VERSION "created by canmatrix"

NS_ :

BS_:

BU_: Tester RRLCMA RLLCMA GWM FRLCM FLLCM

BO_ 2161836032 ExtendIdTest: 8 Tester
 SG_ ExtData : 7|64@0- (1,0) [0|0] ""  RLLCMA,RRLCMA

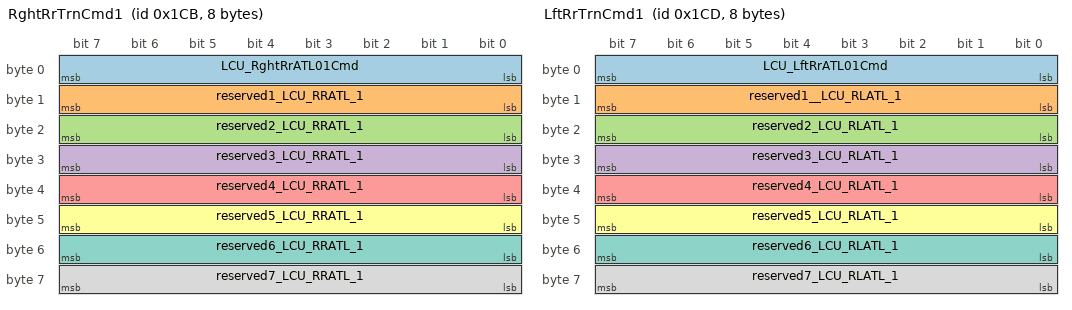
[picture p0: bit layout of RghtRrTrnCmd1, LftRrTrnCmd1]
BO_ 459 RghtRrTrnCmd1: 8 GWM
 SG_ LCU_RghtRrATL01Cmd : 7|8@0+ (1,0) [0|255] ""  RRLCMA
 SG_ reserved1_LCU_RRATL_1 : 15|8@0+ (1,0) [0|255] ""  RRLCMA
 SG_ reserved2_LCU_RRATL_1 : 23|8@0+ (1,0) [0|255] ""  RRLCMA
 SG_ reserved3_LCU_RRATL_1 : 31|8@0+ (1,0) [0|255] ""  RRLCMA
 SG_ reserved4_LCU_RRATL_1 : 39|8@0+ (1,0) [0|255] ""  RRLCMA
 SG_ reserved5_LCU_RRATL_1 : 47|8@0+ (1,0) [0|255] ""  RRLCMA
 SG_ reserved6_LCU_RRATL_1 : 55|8@0+ (1,0) [0|255] ""  RRLCMA
 SG_ reserved7_LCU_RRATL_1 : 63|8@0+ (1,0) [0|255] ""  RRLCMA

BO_ 461 LftRrTrnCmd1: 8 GWM
 SG_ LCU_LftRrATL01Cmd : 7|8@0+ (1,0) [0|255] ""  RLLCMA
 SG_ reserved1__LCU_RLATL_1 : 15|8@0+ (1,0) [0|255] ""  RLLCMA
 SG_ reserved2_LCU_RLATL_1 : 23|8@0+ (1,0) [0|255] ""  RLLCMA
 SG_ reserved3_LCU_RLATL_1 : 31|8@0+ (1,0) [0|255] ""  RLLCMA
 SG_ reserved4_LCU_RLATL_1 : 39|8@0+ (1,0) [0|255] ""  RLLCMA
 SG_ reserved5_LCU_RLATL_1 : 47|8@0+ (1,0) [0|255] ""  RLLCMA
 SG_ reserved6_LCU_RLATL_1 : 55|8@0+ (1,0) [0|255] ""  RLLCMA
 SG_ reserved7_LCU_RLATL_1 : 63|8@0+ (1,0) [0|255] ""  RLLCMA

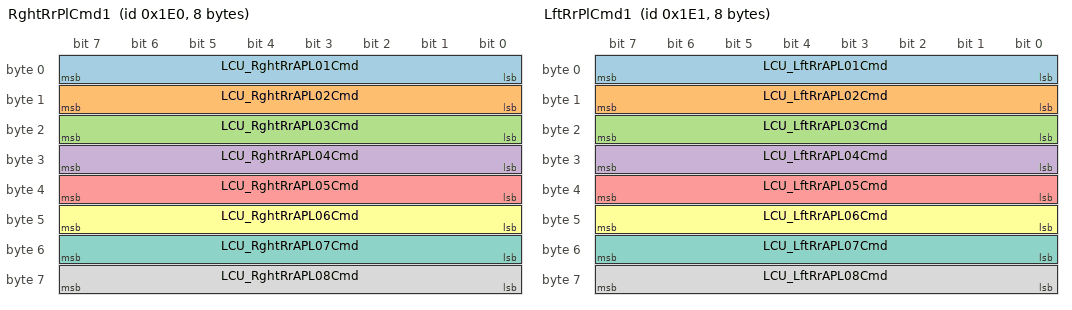
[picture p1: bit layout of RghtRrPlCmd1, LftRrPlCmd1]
BO_ 480 RghtRrPlCmd1: 8 GWM
 SG_ LCU_RghtRrAPL01Cmd : 7|8@0+ (1,0) [0|255] ""  RRLCMA
 SG_ LCU_RghtRrAPL02Cmd : 15|8@0+ (1,0) [0|255] ""  RRLCMA
 SG_ LCU_RghtRrAPL03Cmd : 23|8@0+ (1,0) [0|255] ""  RRLCMA
 SG_ LCU_RghtRrAPL04Cmd : 31|8@0+ (1,0) [0|255] ""  RRLCMA
 SG_ LCU_RghtRrAPL05Cmd : 39|8@0+ (1,0) [0|255] ""  RRLCMA
 SG_ LCU_RghtRrAPL06Cmd : 47|8@0+ (1,0) [0|255] ""  RRLCMA
 SG_ LCU_RghtRrAPL07Cmd : 55|8@0+ (1,0) [0|255] ""  RRLCMA
 SG_ LCU_RghtRrAPL08Cmd : 63|8@0+ (1,0) [0|255] ""  RRLCMA

BO_ 481 LftRrPlCmd1: 8 GWM
 SG_ LCU_LftRrAPL01Cmd : 7|8@0+ (1,0) [0|255] ""  RLLCMA
 SG_ LCU_LftRrAPL02Cmd : 15|8@0+ (1,0) [0|255] ""  RLLCMA
 SG_ LCU_LftRrAPL03Cmd : 23|8@0+ (1,0) [0|255] ""  RLLCMA
 SG_ LCU_LftRrAPL04Cmd : 31|8@0+ (1,0) [0|255] ""  RLLCMA
 SG_ LCU_LftRrAPL05Cmd : 39|8@0+ (1,0) [0|255] ""  RLLCMA
 SG_ LCU_LftRrAPL06Cmd : 47|8@0+ (1,0) [0|255] ""  RLLCMA
 SG_ LCU_LftRrAPL07Cmd : 55|8@0+ (1,0) [0|255] ""  RLLCMA
 SG_ LCU_LftRrAPL08Cmd : 63|8@0+ (1,0) [0|255] ""  RLLCMA

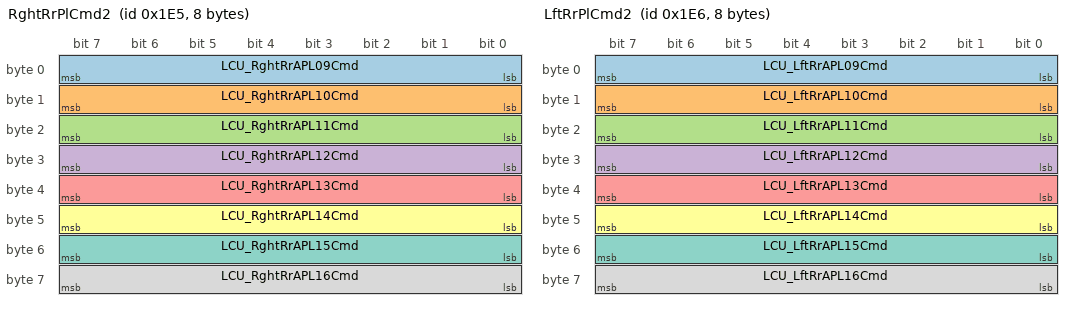
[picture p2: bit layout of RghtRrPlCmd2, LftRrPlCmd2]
BO_ 485 RghtRrPlCmd2: 8 GWM
 SG_ LCU_RghtRrAPL09Cmd : 7|8@0+ (1,0) [0|255] ""  RRLCMA
 SG_ LCU_RghtRrAPL10Cmd : 15|8@0+ (1,0) [0|255] ""  RRLCMA
 SG_ LCU_RghtRrAPL11Cmd : 23|8@0+ (1,0) [0|255] ""  RRLCMA
 SG_ LCU_RghtRrAPL12Cmd : 31|8@0+ (1,0) [0|255] ""  RRLCMA
 SG_ LCU_RghtRrAPL13Cmd : 39|8@0+ (1,0) [0|255] ""  RRLCMA
 SG_ LCU_RghtRrAPL14Cmd : 47|8@0+ (1,0) [0|255] ""  RRLCMA
 SG_ LCU_RghtRrAPL15Cmd : 55|8@0+ (1,0) [0|255] ""  RRLCMA
 SG_ LCU_RghtRrAPL16Cmd : 63|8@0+ (1,0) [0|255] ""  RRLCMA

BO_ 486 LftRrPlCmd2: 8 GWM
 SG_ LCU_LftRrAPL09Cmd : 7|8@0+ (1,0) [0|255] ""  RLLCMA
 SG_ LCU_LftRrAPL10Cmd : 15|8@0+ (1,0) [0|255] ""  RLLCMA
 SG_ LCU_LftRrAPL11Cmd : 23|8@0+ (1,0) [0|255] ""  RLLCMA
 SG_ LCU_LftRrAPL12Cmd : 31|8@0+ (1,0) [0|255] ""  RLLCMA
 SG_ LCU_LftRrAPL13Cmd : 39|8@0+ (1,0) [0|255] ""  RLLCMA
 SG_ LCU_LftRrAPL14Cmd : 47|8@0+ (1,0) [0|255] ""  RLLCMA
 SG_ LCU_LftRrAPL15Cmd : 55|8@0+ (1,0) [0|255] ""  RLLCMA
 SG_ LCU_LftRrAPL16Cmd : 63|8@0+ (1,0) [0|255] ""  RLLCMA

BO_ 489 LCU_MASTER_1: 8 GWM
 SG_ EMS_BatteryReadySt : 52|1@0+ (1,0) [0|1] "" Vector__XXX
 SG_ LCU_WelShwSts : 7|4@0+ (1,0) [0|15] ""  RRLCMA,RLLCMA,FRLCM,FLLCM
 SG_ LCU_LightShwSts : 3|4@0+ (1,0) [0|15] ""  RRLCMA,RLLCMA,FRLCM,FLLCM
 SG_ LCU_LftFrntPlSts : 15|2@0+ (1,0) [0|3] ""  RRLCMA,RLLCMA,FRLCM,FLLCM
 SG_ LCU_RghtDrlSts : 13|1@0+ (1,0) [0|1] ""  RRLCMA,RLLCMA,FRLCM,FLLCM
 SG_ LCU_LftDrlSts : 12|1@0+ (1,0) [0|1] ""  RRLCMA,RLLCMA,FRLCM,FLLCM
 SG_ LCU_RghtTrnSts : 9|1@0+ (1,0) [0|1] ""  RRLCMA,RLLCMA,FRLCM,FLLCM
 SG_ LCU_LftTrnSts : 8|1@0+ (1,0) [0|1] ""  RRLCMA,RLLCMA,FRLCM,FLLCM
 SG_ LCU_FrntFogSts : 23|1@0+ (1,0) [0|1] ""  RRLCMA,RLLCMA,FRLCM,FLLCM
 SG_ LCU_HbSts : 22|2@0+ (1,0) [0|3] ""  RRLCMA,RLLCMA,FRLCM,FLLCM
 SG_ LCU_LbSts : 20|1@0+ (1,0) [0|1] ""  RRLCMA,RLLCMA,FRLCM,FLLCM
 SG_ LCU_RghtRrPlSts : 19|1@0+ (1,0) [0|1] ""  RRLCMA,RLLCMA,FRLCM,FLLCM
 SG_ LCU_LftRrPlSts : 18|1@0+ (1,0) [0|1] ""  RRLCMA,RLLCMA,FRLCM,FLLCM
 SG_ LCU_RghtFrntPlSts : 17|2@0+ (1,0) [0|3] ""  RRLCMA,RLLCMA,FRLCM,FLLCM
 SG_ LCU_Fan2Cmd : 27|1@0+ (1,0) [0|1] ""  RRLCMA,RLLCMA,FRLCM,FLLCM
 SG_ LCU_Fan1Cmd : 26|1@0+ (1,0) [0|1] ""  RRLCMA,RLLCMA,FRLCM,FLLCM
 SG_ LCU_RrFogSts : 25|1@0+ (1,0) [0|1] ""  RRLCMA,RLLCMA,FRLCM,FLLCM
 SG_ LCU_StopSts : 24|1@0+ (1,0) [0|1] ""  RRLCMA,RLLCMA,FRLCM,FLLCM
 SG_ BCS_VehSpdVD : 37|1@0+ (1,0) [0|1] ""  RRLCMA,RLLCMA,FRLCM,FLLCM
 SG_ BCS_VehSpd : 36|13@0+ (0.05625,0) [0|8191] "km/h"  RRLCMA,RLLCMA,FRLCM,FLLCM
 SG_ EMS_EngCrankSt : 51|1@0+ (1,0) [0|1] ""  RRLCMA,RLLCMA,FRLCM,FLLCM
 SG_ EMS_EngSt : 50|1@0+ (1,0) [0|1] ""  RRLCMA,RLLCMA,FRLCM,FLLCM
 SG_ BCM_KeySt : 49|2@0+ (1,0) [0|3] ""  RRLCMA,RLLCMA,FRLCM,FLLCM

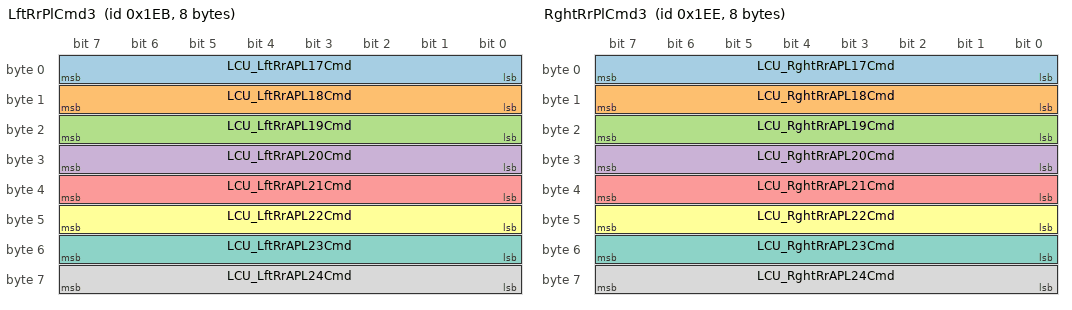
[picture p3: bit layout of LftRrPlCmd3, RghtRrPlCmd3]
BO_ 491 LftRrPlCmd3: 8 GWM
 SG_ LCU_LftRrAPL17Cmd : 7|8@0+ (1,0) [0|255] ""  RLLCMA
 SG_ LCU_LftRrAPL18Cmd : 15|8@0+ (1,0) [0|255] ""  RLLCMA
 SG_ LCU_LftRrAPL19Cmd : 23|8@0+ (1,0) [0|255] ""  RLLCMA
 SG_ LCU_LftRrAPL20Cmd : 31|8@0+ (1,0) [0|255] ""  RLLCMA
 SG_ LCU_LftRrAPL21Cmd : 39|8@0+ (1,0) [0|255] ""  RLLCMA
 SG_ LCU_LftRrAPL22Cmd : 47|8@0+ (1,0) [0|255] ""  RLLCMA
 SG_ LCU_LftRrAPL23Cmd : 55|8@0+ (1,0) [0|255] ""  RLLCMA
 SG_ LCU_LftRrAPL24Cmd : 63|8@0+ (1,0) [0|255] ""  RLLCMA

BO_ 494 RghtRrPlCmd3: 8 GWM
 SG_ LCU_RghtRrAPL17Cmd : 7|8@0+ (1,0) [0|255] ""  RRLCMA
 SG_ LCU_RghtRrAPL18Cmd : 15|8@0+ (1,0) [0|255] ""  RRLCMA
 SG_ LCU_RghtRrAPL19Cmd : 23|8@0+ (1,0) [0|255] ""  RRLCMA
 SG_ LCU_RghtRrAPL20Cmd : 31|8@0+ (1,0) [0|255] ""  RRLCMA
 SG_ LCU_RghtRrAPL21Cmd : 39|8@0+ (1,0) [0|255] ""  RRLCMA
 SG_ LCU_RghtRrAPL22Cmd : 47|8@0+ (1,0) [0|255] ""  RRLCMA
 SG_ LCU_RghtRrAPL23Cmd : 55|8@0+ (1,0) [0|255] ""  RRLCMA
 SG_ LCU_RghtRrAPL24Cmd : 63|8@0+ (1,0) [0|255] ""  RRLCMA

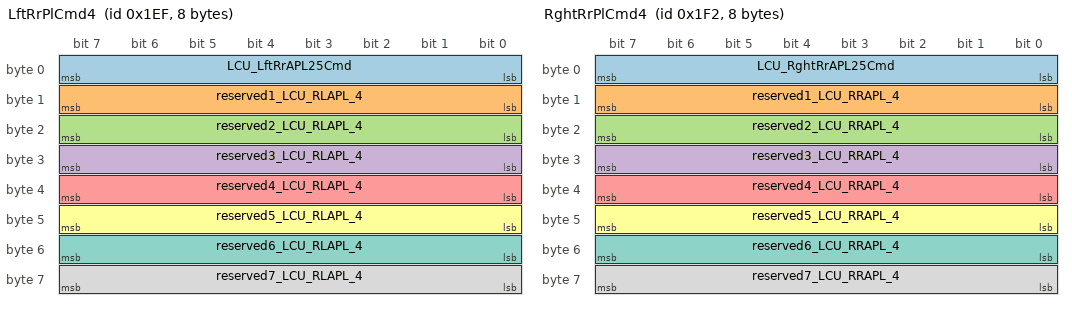
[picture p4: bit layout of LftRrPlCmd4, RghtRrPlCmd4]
BO_ 495 LftRrPlCmd4: 8 GWM
 SG_ LCU_LftRrAPL25Cmd : 7|8@0+ (1,0) [0|255] ""  RLLCMA
 SG_ reserved1_LCU_RLAPL_4 : 15|8@0+ (1,0) [0|255] ""  RLLCMA
 SG_ reserved2_LCU_RLAPL_4 : 23|8@0+ (1,0) [0|255] ""  RLLCMA
 SG_ reserved3_LCU_RLAPL_4 : 31|8@0+ (1,0) [0|255] ""  RLLCMA
 SG_ reserved4_LCU_RLAPL_4 : 39|8@0+ (1,0) [0|255] ""  RLLCMA
 SG_ reserved5_LCU_RLAPL_4 : 47|8@0+ (1,0) [0|255] ""  RLLCMA
 SG_ reserved6_LCU_RLAPL_4 : 55|8@0+ (1,0) [0|255] ""  RLLCMA
 SG_ reserved7_LCU_RLAPL_4 : 63|8@0+ (1,0) [0|255] ""  RLLCMA

BO_ 498 RghtRrPlCmd4: 8 GWM
 SG_ LCU_RghtRrAPL25Cmd : 7|8@0+ (1,0) [0|255] ""  RRLCMA
 SG_ reserved1_LCU_RRAPL_4 : 15|8@0+ (1,0) [0|255] ""  RRLCMA
 SG_ reserved2_LCU_RRAPL_4 : 23|8@0+ (1,0) [0|255] ""  RRLCMA
 SG_ reserved3_LCU_RRAPL_4 : 31|8@0+ (1,0) [0|255] ""  RRLCMA
 SG_ reserved4_LCU_RRAPL_4 : 39|8@0+ (1,0) [0|255] ""  RRLCMA
 SG_ reserved5_LCU_RRAPL_4 : 47|8@0+ (1,0) [0|255] ""  RRLCMA
 SG_ reserved6_LCU_RRAPL_4 : 55|8@0+ (1,0) [0|255] ""  RRLCMA
 SG_ reserved7_LCU_RRAPL_4 : 63|8@0+ (1,0) [0|255] ""  RRLCMA

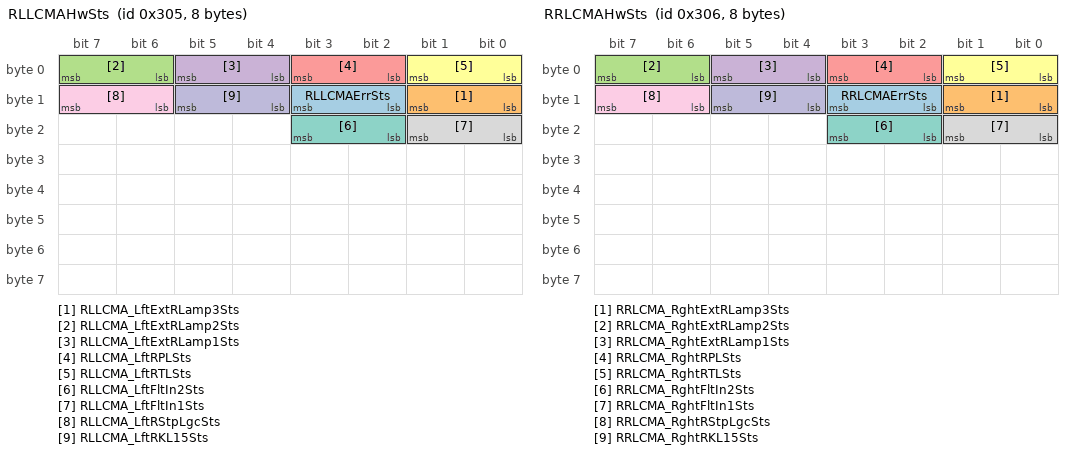
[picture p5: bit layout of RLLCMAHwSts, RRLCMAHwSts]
BO_ 773 RLLCMAHwSts: 8 RLLCMA
 SG_ RLLCMAErrSts : 11|2@0+ (1,0) [0|3] ""  GWM
 SG_ RLLCMA_LftExtRLamp3Sts : 9|2@0+ (1,0) [0|3] ""  GWM
 SG_ RLLCMA_LftExtRLamp2Sts : 7|2@0+ (1,0) [0|3] ""  GWM
 SG_ RLLCMA_LftExtRLamp1Sts : 5|2@0+ (1,0) [0|3] ""  GWM
 SG_ RLLCMA_LftRPLSts : 3|2@0+ (1,0) [0|3] ""  GWM
 SG_ RLLCMA_LftRTLSts : 1|2@0+ (1,0) [0|3] ""  GWM
 SG_ RLLCMA_LftFltIn2Sts : 19|2@0+ (1,0) [0|3] ""  GWM
 SG_ RLLCMA_LftFltIn1Sts : 17|2@0+ (1,0) [0|3] ""  GWM
 SG_ RLLCMA_LftRStpLgcSts : 15|2@0+ (1,0) [0|3] ""  GWM
 SG_ RLLCMA_LftRKL15Sts : 13|2@0+ (1,0) [0|3] ""  GWM

BO_ 774 RRLCMAHwSts: 8 RRLCMA
 SG_ RRLCMAErrSts : 11|2@0+ (1,0) [0|3] ""  GWM
 SG_ RRLCMA_RghtExtRLamp3Sts : 9|2@0+ (1,0) [0|3] ""  GWM
 SG_ RRLCMA_RghtExtRLamp2Sts : 7|2@0+ (1,0) [0|3] ""  GWM
 SG_ RRLCMA_RghtExtRLamp1Sts : 5|2@0+ (1,0) [0|3] ""  GWM
 SG_ RRLCMA_RghtRPLSts : 3|2@0+ (1,0) [0|3] ""  GWM
 SG_ RRLCMA_RghtRTLSts : 1|2@0+ (1,0) [0|3] ""  GWM
 SG_ RRLCMA_RghtFltIn2Sts : 19|2@0+ (1,0) [0|3] ""  GWM
 SG_ RRLCMA_RghtFltIn1Sts : 17|2@0+ (1,0) [0|3] ""  GWM
 SG_ RRLCMA_RghtRStpLgcSts : 15|2@0+ (1,0) [0|3] ""  GWM
 SG_ RRLCMA_RghtRKL15Sts : 13|2@0+ (1,0) [0|3] ""  GWM

BO_ 789 RLLCMALampSts: 8 RLLCMA
 SG_ RLLCMA_Bin2Err : 27|1@0+ (1,0) [0|1] "" Vector__XXX
 SG_ RLLCMA_Bin1Err : 26|1@0+ (1,0) [0|1] "" Vector__XXX
 SG_ RLLCMA_HsssErr : 7|1@0+ (1,0) [0|1] ""  GWM
 SG_ RLLCMA_Cv2Err : 6|1@0+ (1,0) [0|1] ""  GWM
 SG_ RLLCMA_Cv1Err : 5|1@0+ (1,0) [0|1] ""  GWM
 SG_ RLLCMA_LdoErr : 4|1@0+ (1,0) [0|1] ""  GWM
 SG_ RLLCMA_LostLCU : 3|1@0+ (1,0) [0|1] ""  GWM
 SG_ RLLCMA_BusOff : 2|1@0+ (1,0) [0|1] ""  GWM
 SG_ RLLCMA_Uv : 1|1@0+ (1,0) [0|1] ""  GWM
 SG_ RLLCMA_Ov : 0|1@0+ (1,0) [0|1] ""  GWM
 SG_ RLLCMA_Mtrx7Lst : 15|1@0+ (1,0) [0|1] ""  GWM
 SG_ RLLCMA_Mtrx6Lst : 14|1@0+ (1,0) [0|1] ""  GWM
 SG_ RLLCMA_Mtrx5Lst : 13|1@0+ (1,0) [0|1] ""  GWM
 SG_ RLLCMA_Mtrx4Lst : 12|1@0+ (1,0) [0|1] ""  GWM
 SG_ RLLCMA_Mtrx3Lst : 11|1@0+ (1,0) [0|1] ""  GWM
 SG_ RLLCMA_Mtrx2Lst : 10|1@0+ (1,0) [0|1] ""  GWM
 SG_ RLLCMA_Mtrx1Lst : 9|1@0+ (1,0) [0|1] ""  GWM
 SG_ RLLCMA_Mtrx0Lst : 8|1@0+ (1,0) [0|1] ""  GWM
 SG_ RLLCMA_Mtrx7LedErr : 23|1@0+ (1,0) [0|1] ""  GWM
 SG_ RLLCMA_Mtrx6LedErr : 22|1@0+ (1,0) [0|1] ""  GWM
 SG_ RLLCMA_Mtrx5LedErr : 21|1@0+ (1,0) [0|1] ""  GWM
 SG_ RLLCMA_Mtrx4LedErr : 20|1@0+ (1,0) [0|1] ""  GWM
 SG_ RLLCMA_Mtrx3LedErr : 19|1@0+ (1,0) [0|1] ""  GWM
 SG_ RLLCMA_Mtrx2LedErr : 18|1@0+ (1,0) [0|1] ""  GWM
 SG_ RLLCMA_Mtrx1LedErr : 17|1@0+ (1,0) [0|1] ""  GWM
 SG_ RLLCMA_Mtrx0LedErr : 16|1@0+ (1,0) [0|1] ""  GWM
 SG_ RLLCMA_FltIn2Warning : 25|1@0+ (1,0) [0|1] ""  GWM
 SG_ RLLCMA_FltIn1Warning : 24|1@0+ (1,0) [0|1] ""  GWM

BO_ 790 RRLCMALampSts: 8 RRLCMA
 SG_ RRLCMA_Bin2Err : 27|1@0+ (1,0) [0|1] "" Vector__XXX
 SG_ RRLCMA_Bin1Err : 26|1@0+ (1,0) [0|1] "" Vector__XXX
 SG_ RRLCMA_HsssErr : 7|1@0+ (1,0) [0|1] ""  GWM
 SG_ RRLCMA_Cv2Err : 6|1@0+ (1,0) [0|1] ""  GWM
 SG_ RRLCMA_Cv1Err : 5|1@0+ (1,0) [0|1] ""  GWM
 SG_ RRLCMA_LdoErr : 4|1@0+ (1,0) [0|1] ""  GWM
 SG_ RRLCMA_LostLCU : 3|1@0+ (1,0) [0|1] ""  GWM
 SG_ RRLCMA_BusOff : 2|1@0+ (1,0) [0|1] ""  GWM
 SG_ RRLCMA_Uv : 1|1@0+ (1,0) [0|1] ""  GWM
 SG_ RRLCMA_Ov : 0|1@0+ (1,0) [0|1] ""  GWM
 SG_ RRLCMA_Mtrx7Lst : 15|1@0+ (1,0) [0|1] ""  GWM
 SG_ RRLCMA_Mtrx6Lst : 14|1@0+ (1,0) [0|1] ""  GWM
 SG_ RRLCMA_Mtrx5Lst : 13|1@0+ (1,0) [0|1] ""  GWM
 SG_ RRLCMA_Mtrx4Lst : 12|1@0+ (1,0) [0|1] ""  GWM
 SG_ RRLCMA_Mtrx3Lst : 11|1@0+ (1,0) [0|1] ""  GWM
 SG_ RRLCMA_Mtrx2Lst : 10|1@0+ (1,0) [0|1] ""  GWM
 SG_ RRLCMA_Mtrx1Lst : 9|1@0+ (1,0) [0|1] ""  GWM
 SG_ RRLCMA_Mtrx0Lst : 8|1@0+ (1,0) [0|1] ""  GWM
 SG_ RRLCMA_Mtrx7LedErr : 23|1@0+ (1,0) [0|1] ""  GWM
 SG_ RRLCMA_Mtrx6LedErr : 22|1@0+ (1,0) [0|1] ""  GWM
 SG_ RRLCMA_Mtrx5LedErr : 21|1@0+ (1,0) [0|1] ""  GWM
 SG_ RRLCMA_Mtrx4LedErr : 20|1@0+ (1,0) [0|1] ""  GWM
 SG_ RRLCMA_Mtrx3LedErr : 19|1@0+ (1,0) [0|1] ""  GWM
 SG_ RRLCMA_Mtrx2LedErr : 18|1@0+ (1,0) [0|1] ""  GWM
 SG_ RRLCMA_Mtrx1LedErr : 17|1@0+ (1,0) [0|1] ""  GWM
 SG_ RRLCMA_Mtrx0LedErr : 16|1@0+ (1,0) [0|1] ""  GWM
 SG_ RRLCMA_FltIn2Warning : 25|1@0+ (1,0) [0|1] ""  GWM
 SG_ RRLCMA_FltIn1Warning : 24|1@0+ (1,0) [0|1] ""  GWM

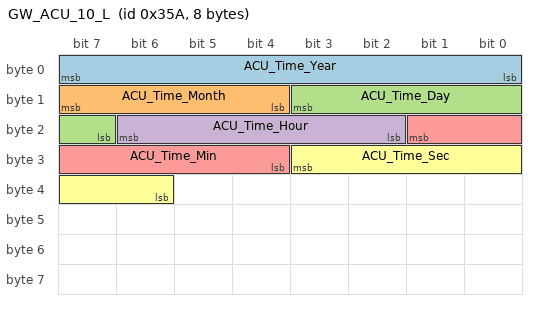
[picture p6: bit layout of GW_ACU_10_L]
BO_ 858 GW_ACU_10_L: 8 GWM
 SG_ ACU_Time_Year : 7|8@0+ (1,0) [0|255] "y"  RRLCMA,RLLCMA,FRLCM,FLLCM
 SG_ ACU_Time_Month : 15|4@0+ (1,0) [0|15] "m"  RRLCMA,RLLCMA,FRLCM,FLLCM
 SG_ ACU_Time_Day : 11|5@0+ (1,0) [0|31] "d"  RRLCMA,RLLCMA,FRLCM,FLLCM
 SG_ ACU_Time_Hour : 22|5@0+ (1,0) [0|31] "h"  RRLCMA,RLLCMA,FRLCM,FLLCM
 SG_ ACU_Time_Min : 17|6@0+ (1,0) [0|63] "min"  RRLCMA,RLLCMA,FRLCM,FLLCM
 SG_ ACU_Time_Sec : 27|6@0+ (1,0) [0|63] "s"  RRLCMA,RLLCMA,FRLCM,FLLCM

BO_ 1358 Nm_RLLCMA: 8 RLLCMA
 SG_ RLLCMA_NMNodeAddress : 7|8@0+ (1,0) [0|255] "-"  RRLCMA,GWM,FRLCM,FLLCM
 SG_ RLLCMA_NMDataField : 15|56@0+ (1,0) [0|7.20575940379279E+016] "-"  RRLCMA,GWM,FRLCM,FLLCM

BO_ 1359 Nm_LCU: 8 GWM
 SG_ GWM_NodeAddress : 7|8@0+ (1,0) [0|255] ""  RRLCMA,RLLCMA,FRLCM,FLLCM
 SG_ GWM_NMDataField : 15|56@0+ (1,0) [0|7.20575940379279E+016] ""  RRLCMA,RLLCMA,FRLCM,FLLCM

BO_ 1371 Nm_RRLCMA: 8 RRLCMA
 SG_ RRLCMA_NMNodeAddress : 7|8@0+ (1,0) [0|255] "-"  RLLCMA,GWM,FRLCM,FLLCM
 SG_ RRLCMA_NMDataField : 15|56@0+ (1,0) [0|7.20575940379279E+016] "-"  RLLCMA,GWM,FRLCM,FLLCM

BO_ 1870 PhyDiagReq_LftRrA: 8 Tester
 SG_ RLLCMA_Diag_Request : 7|64@0+ (1,0) [0|1.84467440737096E+019] ""  RLLCMA

BO_ 1883 PhyDiagReq_RghtRrA: 8 Tester
 SG_ RRLCMA_Diag_Request : 7|64@0+ (1,0) [0|1.84467440737096E+019] ""  RRLCMA

BO_ 1998 DiagResp_LftRrA: 8 RLLCMA
 SG_ RLLCMA_Diag_Response : 7|64@0+ (1,0) [0|1.84467440737096E+019] ""  Tester

BO_ 2011 DiagResp_RghtRrA: 8 RRLCMA
 SG_ RRLCMA_Diag_Response : 7|64@0+ (1,0) [0|1.84467440737096E+019] ""  Tester

BO_ 2015 FuncDiagReq: 8 Tester
 SG_ Func_Diag_Rx : 7|64@0+ (1,0) [0|1.84467440737096E+019] ""  RRLCMA,RLLCMA,FRLCM,FLLCM

CM_ BO_ 459 "LCU_RRATL_1";
CM_ SG_ 459 LCU_RghtRrATL01Cmd "Right rear A turn lamp 01 command";
CM_ BO_ 461 "LCU_RLATL_1";
CM_ SG_ 461 LCU_LftRrATL01Cmd "left rear A turn lamp 01 command";
CM_ BO_ 480 "LCU_RRAPL_1";
CM_ SG_ 480 LCU_RghtRrAPL01Cmd "Right rear A postion lamp 01 command";
CM_ SG_ 480 LCU_RghtRrAPL02Cmd "Right rear A postion lamp 02 command";
CM_ SG_ 480 LCU_RghtRrAPL03Cmd "Right rear A postion lamp 03 command";
CM_ SG_ 480 LCU_RghtRrAPL04Cmd "Right rear A postion lamp 04 command";
CM_ SG_ 480 LCU_RghtRrAPL05Cmd "Right rear A postion lamp 05 command";
CM_ SG_ 480 LCU_RghtRrAPL06Cmd "Right rear A postion lamp 06 command";
CM_ SG_ 480 LCU_RghtRrAPL07Cmd "Right rear A postion lamp 07 command";
CM_ SG_ 480 LCU_RghtRrAPL08Cmd "Right rear A postion lamp 08 command";
CM_ BO_ 481 "LCU_RLAPL_1";
CM_ SG_ 481 LCU_LftRrAPL01Cmd "Left rear A postion lamp 01 command";
CM_ SG_ 481 LCU_LftRrAPL02Cmd "Left rear A postion lamp 02 command";
CM_ SG_ 481 LCU_LftRrAPL03Cmd "Left rear A postion lamp 03 command";
CM_ SG_ 481 LCU_LftRrAPL04Cmd "Left rear A postion lamp 04 command";
CM_ SG_ 481 LCU_LftRrAPL05Cmd "Left rear A postion lamp 05 command";
CM_ SG_ 481 LCU_LftRrAPL06Cmd "Left rear A postion lamp 06 command";
CM_ SG_ 481 LCU_LftRrAPL07Cmd "Left rear A postion lamp 07 command";
CM_ SG_ 481 LCU_LftRrAPL08Cmd "Left rear A postion lamp 08 command";
CM_ BO_ 485 "LCU_RRAPL_2";
CM_ SG_ 485 LCU_RghtRrAPL09Cmd "Right rear A postion lamp 09 command";
CM_ SG_ 485 LCU_RghtRrAPL10Cmd "Right rear A postion lamp 10 command";
CM_ SG_ 485 LCU_RghtRrAPL11Cmd "Right rear A postion lamp 11 command";
CM_ SG_ 485 LCU_RghtRrAPL12Cmd "Right rear A postion lamp 12 command";
CM_ SG_ 485 LCU_RghtRrAPL13Cmd "Right rear A postion lamp 13 command";
CM_ SG_ 485 LCU_RghtRrAPL14Cmd "Right rear A postion lamp 14 command";
CM_ SG_ 485 LCU_RghtRrAPL15Cmd "Right rear A postion lamp 15 command";
CM_ SG_ 485 LCU_RghtRrAPL16Cmd "Right rear A postion lamp 16 command";
CM_ BO_ 486 "LCU_RLAPL_2";
CM_ SG_ 486 LCU_LftRrAPL09Cmd "Left rear A postion lamp 09 command";
CM_ SG_ 486 LCU_LftRrAPL10Cmd "Left rear A postion lamp 10 command";
CM_ SG_ 486 LCU_LftRrAPL11Cmd "Left rear A postion lamp 11 command";
CM_ SG_ 486 LCU_LftRrAPL12Cmd "Left rear A postion lamp 12 command";
CM_ SG_ 486 LCU_LftRrAPL13Cmd "Left rear A postion lamp 13 command";
CM_ SG_ 486 LCU_LftRrAPL14Cmd "Left rear A postion lamp 14 command";
CM_ SG_ 486 LCU_LftRrAPL15Cmd "Left rear A postion lamp 15 command";
CM_ SG_ 486 LCU_LftRrAPL16Cmd "Left rear A postion lamp 16 command";
CM_ BO_ 489 "LCU_MASTER_1";
CM_ SG_ 489 EMS_BatteryReadySt "Battery Ready status";
CM_ SG_ 489 LCU_WelShwSts "Welcome show status";
CM_ SG_ 489 LCU_LightShwSts "light show status";
CM_ SG_ 489 LCU_LftFrntPlSts "left front postion lamp status";
CM_ SG_ 489 LCU_RghtDrlSts "right day time running lamp status";
CM_ SG_ 489 LCU_LftDrlSts "left day time running lamp status";
CM_ SG_ 489 LCU_RghtTrnSts "right turn lamp status";
CM_ SG_ 489 LCU_LftTrnSts "left turn lamp status";
CM_ SG_ 489 LCU_FrntFogSts "front fog lamp status";
CM_ SG_ 489 LCU_HbSts "high beam lamp status";
CM_ SG_ 489 LCU_LbSts "low beam lamp status";
CM_ SG_ 489 LCU_RghtRrPlSts "right rear postion lamp status";
CM_ SG_ 489 LCU_LftRrPlSts "left rear postion lamp status";
CM_ SG_ 489 LCU_RghtFrntPlSts "right front postion lamp status";
CM_ SG_ 489 LCU_Fan2Cmd "cool fan2 control command";
CM_ SG_ 489 LCU_Fan1Cmd "cool fan1 control command";
CM_ SG_ 489 LCU_RrFogSts "rear fog lampstatus";
CM_ SG_ 489 LCU_StopSts "stop lamp status";
CM_ SG_ 489 BCS_VehSpdVD "Quality/fault information to vehicle speed";
CM_ SG_ 489 BCS_VehSpd "Vehicle speed";
CM_ SG_ 489 EMS_EngCrankSt "Engine crank status";
CM_ SG_ 489 EMS_EngSt "Engine running status";
CM_ SG_ 489 BCM_KeySt "Ignition key position status";
CM_ BO_ 491 "LCU_RLAPL_3";
CM_ SG_ 491 LCU_LftRrAPL17Cmd "Left rear A postion lamp 17 command";
CM_ SG_ 491 LCU_LftRrAPL18Cmd "Left rear A postion lamp 18 command";
CM_ SG_ 491 LCU_LftRrAPL19Cmd "Left rear A postion lamp 19 command";
CM_ SG_ 491 LCU_LftRrAPL20Cmd "Left rear A postion lamp 20 command";
CM_ SG_ 491 LCU_LftRrAPL21Cmd "Left rear A postion lamp 21 command";
CM_ SG_ 491 LCU_LftRrAPL22Cmd "Left rear A postion lamp 22 command";
CM_ SG_ 491 LCU_LftRrAPL23Cmd "Left rear A postion lamp 23 command";
CM_ SG_ 491 LCU_LftRrAPL24Cmd "Left rear A postion lamp 24 command";
CM_ BO_ 494 "LCU_RRAPL_3";
CM_ SG_ 494 LCU_RghtRrAPL17Cmd "Right rear A postion lamp 17 command";
CM_ SG_ 494 LCU_RghtRrAPL18Cmd "Right rear A postion lamp 18 command";
CM_ SG_ 494 LCU_RghtRrAPL19Cmd "Right rear A postion lamp 19 command";
CM_ SG_ 494 LCU_RghtRrAPL20Cmd "Right rear A postion lamp 20 command";
CM_ SG_ 494 LCU_RghtRrAPL21Cmd "Right rear A postion lamp 21 command";
CM_ SG_ 494 LCU_RghtRrAPL22Cmd "Right rear A postion lamp 22 command";
CM_ SG_ 494 LCU_RghtRrAPL23Cmd "Right rear A postion lamp 23 command";
CM_ SG_ 494 LCU_RghtRrAPL24Cmd "Right rear A postion lamp 24 command";
CM_ BO_ 495 "LCU_RLAPL_4";
CM_ SG_ 495 LCU_LftRrAPL25Cmd "Left rear A postion lamp 25 command";
CM_ BO_ 498 "LCU_RRAPL_4";
CM_ SG_ 498 LCU_RghtRrAPL25Cmd "Right rear A postion lamp 25 command";
CM_ BO_ 773 "RLLCMA_LCU_1";
CM_ SG_ 773 RLLCMAErrSts "RLLCMA module inner work status";
CM_ SG_ 773 RLLCMA_LftExtRLamp3Sts "RLLCMA left external rear lamp3 work status";
CM_ SG_ 773 RLLCMA_LftExtRLamp2Sts "RLLCMA left external rear lamp2 work status";
CM_ SG_ 773 RLLCMA_LftExtRLamp1Sts "RLLCMA left external rear lamp1 work status";
CM_ SG_ 773 RLLCMA_LftRPLSts "RLLCMA left rear position lamp work status";
CM_ SG_ 773 RLLCMA_LftRTLSts "RLLCMA left rear turn lamp work status";
CM_ SG_ 773 RLLCMA_LftFltIn2Sts "RLLCMA Left fault-in logic input2 status";
CM_ SG_ 773 RLLCMA_LftFltIn1Sts "RLLCMA Left fault-in logic input1 status";
CM_ SG_ 773 RLLCMA_LftRStpLgcSts "RLLCMA Left rear stop lamp logic input status";
CM_ SG_ 773 RLLCMA_LftRKL15Sts "RLLCMA Left rear lamp KL15 input status";
CM_ BO_ 774 "RRLCMA_LCU_1";
CM_ SG_ 774 RRLCMAErrSts "RRLCMA module inner work status";
CM_ SG_ 774 RRLCMA_RghtExtRLamp3Sts "RRLCMA Right external rear lamp3 work status";
CM_ SG_ 774 RRLCMA_RghtExtRLamp2Sts "RRLCMA Right external rear lamp2 work status";
CM_ SG_ 774 RRLCMA_RghtExtRLamp1Sts "RRLCMA Right external rear lamp1 work status";
CM_ SG_ 774 RRLCMA_RghtRPLSts "RRLCMA Right rear position lamp work status";
CM_ SG_ 774 RRLCMA_RghtRTLSts "RRLCMA Right rear turn lamp work status";
CM_ SG_ 774 RRLCMA_RghtFltIn2Sts "RRLCMA Right fault-in logic input2 status";
CM_ SG_ 774 RRLCMA_RghtFltIn1Sts "RRLCMA Right  fault-in logic input1 status";
CM_ SG_ 774 RRLCMA_RghtRStpLgcSts "RRLCMA Right rear stop lamp logic input status";
CM_ SG_ 774 RRLCMA_RghtRKL15Sts "RRLCMA Right rear lamp KL15 input status";
CM_ BO_ 789 "RLLCMA_LCU_2";
CM_ SG_ 789 RLLCMA_Bin2Err "RLLCMA power channel 2 bin fault";
CM_ SG_ 789 RLLCMA_Bin1Err "RLLCMA power channel 1 bin fault";
CM_ SG_ 789 RLLCMA_HsssErr "RLLCMA HSSS channel current out of range";
CM_ SG_ 789 RLLCMA_Cv2Err "RLLCMA constant voltage power channel2 error";
CM_ SG_ 789 RLLCMA_Cv1Err "RLLCMA constant voltage power channel1 error";
CM_ SG_ 789 RLLCMA_LdoErr "RLLCMA output 5V error";
CM_ SG_ 789 RLLCMA_LostLCU "RLLCMA module lost communication with LCU";
CM_ SG_ 789 RLLCMA_BusOff "RLLCMA module can bus off";
CM_ SG_ 789 RLLCMA_Uv "RLLCMA module power undervoltage";
CM_ SG_ 789 RLLCMA_Ov "RLLCMA module power overvoltage";
CM_ SG_ 789 RLLCMA_Mtrx7Lst "RLLCMA module lost communication with matrix chip 7#";
CM_ SG_ 789 RLLCMA_Mtrx6Lst "RLLCMA module lost communication with matrix chip 6#";
CM_ SG_ 789 RLLCMA_Mtrx5Lst "RLLCMA module lost communication with matrix chip 5#";
CM_ SG_ 789 RLLCMA_Mtrx4Lst "RLLCMA module lost communication with matrix chip 4#";
CM_ SG_ 789 RLLCMA_Mtrx3Lst "RLLCMA module lost communication with matrix chip 3#";
CM_ SG_ 789 RLLCMA_Mtrx2Lst "RLLCMA module lost communication with matrix chip 2#";
CM_ SG_ 789 RLLCMA_Mtrx1Lst "RLLCMA module lost communication with matrix chip 1#";
CM_ SG_ 789 RLLCMA_Mtrx0Lst "RLLCMA module lost communication with matrix chip 0#";
CM_ SG_ 789 RLLCMA_Mtrx7LedErr "RLLCMA Matrix chip 7# led error";
CM_ SG_ 789 RLLCMA_Mtrx6LedErr "RLLCMA Matrix chip 6# led error";
CM_ SG_ 789 RLLCMA_Mtrx5LedErr "RLLCMA Matrix chip 5# led error";
CM_ SG_ 789 RLLCMA_Mtrx4LedErr "RLLCMA Matrix chip 4# led error";
CM_ SG_ 789 RLLCMA_Mtrx3LedErr "RLLCMA Matrix chip 3# led error";
CM_ SG_ 789 RLLCMA_Mtrx2LedErr "RLLCMA Matrix chip 2# led error";
CM_ SG_ 789 RLLCMA_Mtrx1LedErr "RLLCMA Matrix chip 1# led error";
CM_ SG_ 789 RLLCMA_Mtrx0LedErr "RLLCMA Matrix chip 0# led error";
CM_ SG_ 789 RLLCMA_FltIn2Warning "RLLCMA fault input2 warning";
CM_ SG_ 789 RLLCMA_FltIn1Warning "RLLCMA fault input1 warning";
CM_ BO_ 790 "RRLCMA_LCU_2";
CM_ SG_ 790 RRLCMA_Bin2Err "RRLCMA power channel 2 bin fault";
CM_ SG_ 790 RRLCMA_Bin1Err "RRLCMA power channel 1 bin fault";
CM_ SG_ 790 RRLCMA_HsssErr "RRLCMA HSSS channel current out of range";
CM_ SG_ 790 RRLCMA_Cv2Err "RRLCMA constant voltage power channel2 error";
CM_ SG_ 790 RRLCMA_Cv1Err "RRLCMA constant voltage power channel1 error";
CM_ SG_ 790 RRLCMA_LdoErr "RRLCMA output 5V error";
CM_ SG_ 790 RRLCMA_LostLCU "RRLCMA module lost communication with LCU";
CM_ SG_ 790 RRLCMA_BusOff "RRLCMA module can bus off";
CM_ SG_ 790 RRLCMA_Uv "RRLCMA module power undervoltage";
CM_ SG_ 790 RRLCMA_Ov "RRLCMA module power overvoltage";
CM_ SG_ 790 RRLCMA_Mtrx7Lst "RRLCMA module lost communication with matrix chip 7#";
CM_ SG_ 790 RRLCMA_Mtrx6Lst "RRLCMA module lost communication with matrix chip 6#";
CM_ SG_ 790 RRLCMA_Mtrx5Lst "RRLCMA module lost communication with matrix chip 5#";
CM_ SG_ 790 RRLCMA_Mtrx4Lst "RRLCMA module lost communication with matrix chip 4#";
CM_ SG_ 790 RRLCMA_Mtrx3Lst "RRLCMA module lost communication with matrix chip 3#";
CM_ SG_ 790 RRLCMA_Mtrx2Lst "RRLCMA module lost communication with matrix chip 2#";
CM_ SG_ 790 RRLCMA_Mtrx1Lst "RRLCMA module lost communication with matrix chip 1#";
CM_ SG_ 790 RRLCMA_Mtrx0Lst "RRLCMA module lost communication with matrix chip 0#";
CM_ SG_ 790 RRLCMA_Mtrx7LedErr "RRLCMA Matrix chip 7# led error";
CM_ SG_ 790 RRLCMA_Mtrx6LedErr "RRLCMA Matrix chip 6# led error";
CM_ SG_ 790 RRLCMA_Mtrx5LedErr "RRLCMA Matrix chip 5# led error";
CM_ SG_ 790 RRLCMA_Mtrx4LedErr "RRLCMA Matrix chip 4# led error";
CM_ SG_ 790 RRLCMA_Mtrx3LedErr "RRLCMA Matrix chip 3# led error";
CM_ SG_ 790 RRLCMA_Mtrx2LedErr "RRLCMA Matrix chip 2# led error";
CM_ SG_ 790 RRLCMA_Mtrx1LedErr "RRLCMA Matrix chip 1# led error";
CM_ SG_ 790 RRLCMA_Mtrx0LedErr "RRLCMA Matrix chip 0# led error";
CM_ SG_ 790 RRLCMA_FltIn2Warning "RRLCMA fault input2 warning";
CM_ SG_ 790 RRLCMA_FltIn1Warning "RRLCMA fault input1 warning";
CM_ BO_ 858 "GW_ACU_10_L";
CM_ SG_ 858 ACU_Time_Year "Year number";
CM_ SG_ 858 ACU_Time_Month "Month number";
CM_ SG_ 858 ACU_Time_Day "Day number";
CM_ SG_ 858 ACU_Time_Hour "Hour number";
CM_ SG_ 858 ACU_Time_Min "Minute number";
CM_ SG_ 858 ACU_Time_Sec "Second number";
CM_ BO_ 1358 "RLLCMA_NM_LCAN";
CM_ SG_ 1358 RLLCMA_NMNodeAddress "RLLCMA  node address";
CM_ SG_ 1358 RLLCMA_NMDataField "RLLCMA Network management data";
CM_ BO_ 1359 "GWM_LCAN_NM";
CM_ SG_ 1359 GWM_NodeAddress "GWM node adress";
CM_ SG_ 1359 GWM_NMDataField "GWM Network management data";
CM_ BO_ 1371 "RRLCMA_NM_LCAN";
CM_ SG_ 1371 RRLCMA_NMNodeAddress "RRLCMA  node address";
CM_ SG_ 1371 RRLCMA_NMDataField "RRLCMA Network management data";
CM_ BO_ 1870 "RLLCMA_Diag_Rx";
CM_ SG_ 1870 RLLCMA_Diag_Request "Diagnostic physical request";
CM_ BO_ 1883 "RRLCMA_Diag_Rx";
CM_ SG_ 1883 RRLCMA_Diag_Request "Diagnostic physical request";
CM_ BO_ 1998 "RLLCMA_Diag_Tx";
CM_ SG_ 1998 RLLCMA_Diag_Response "Diagnostic  response";
CM_ BO_ 2011 "RRLCMA_Diag_Tx";
CM_ SG_ 2011 RRLCMA_Diag_Response "Diagnostic  response";
BA_DEF_ BO_  "GenMsgSendType" ENUM  "Cyclic","NotUsed","NotUsed","NotUsed","NotUsed","NotUsed","NotUsed","NotUsed","NoMsgSendType";
BA_DEF_ SG_  "GenSigSendOnInit" ENUM  "Not Initialized","Application","Handler";
BA_DEF_ SG_  "GenSigSendType" ENUM  "NotUsed","OnWrite","OnWriteWithRepetition","OnChange","OnChangeWithRepetition","IfActive","IfActiveWithRepeition","NoSigSendType";
BA_DEF_ BO_  "GenMsgILSupport" ENUM  "No","Yes";
BA_DEF_ BO_  "DiagRequest" ENUM  "No","Yes";
BA_DEF_ BO_  "DiagResponse" ENUM  "No","Yes";
BA_DEF_ BO_  "DiagState" ENUM  "No","Yes";
BA_DEF_ BO_  "MessageSubnet" ENUM  "BB","PB","CB","Body","HS","Powertrain","Chassis","Spare","PE","CC";
BA_DEF_ BU_  "ECU_Id" HEX 0 255;
BA_DEF_ BU_  "ILUsed" ENUM  "No","Yes";
BA_DEF_ BU_  "SourceId" HEX 0 255;
BA_DEF_ BU_  "NmAsrNode" ENUM  "No","Yes";
BA_DEF_ BU_  "NmAsrNodeIdentifier" HEX 0 159;
BA_DEF_ BU_  "NmAsrCanMsgReducedTime" INT 0 65535;
BA_DEF_  "DBName" STRING ;
BA_DEF_  "NmType" STRING ;
BA_DEF_  "Baudrate" INT 0 1000000;
BA_DEF_  "BusOffRecoveryTime" INT 0 65535;
BA_DEF_  "Manufacturer" STRING ;
BA_DEF_  "SamplePointMin" FLOAT 0 100;
BA_DEF_  "SamplePointMax" FLOAT 0 100;
BA_DEF_  "SyncJumpWidthMin" INT 0 255;
BA_DEF_  "SyncJumpWidthMax" INT 0 255;
BA_DEF_  "BusType" STRING ;
BA_DEF_  "NmAsrMessageCount" INT 0 256;
BA_DEF_  "NmAsrBaseAddress" HEX 0 2032;
BA_DEF_  "NmAsrTimeoutTime" INT 0 65535;
BA_DEF_  "NmAsrWaitBusSleepTime" INT 0 65535;
BA_DEF_  "NmAsrRepeatMessageTime" INT 0 65525;
BA_DEF_  "NmAsrCanMsgCycleTime" INT 0 65535;
BA_DEF_ BO_  "GenMsgCycleTime" INT 0 65535;
BA_DEF_ BU_ "NodeLayerModules" STRING ;
BA_DEF_REL_ BU_SG_REL_  "GenSigTimeoutMsg" HEX 0 65535;
BA_DEF_REL_ BU_SG_REL_  "GenSigTimeoutTime" INT 0 15000;
BA_DEF_DEF_  "GenMsgSendType" "NoMsgSendType";
BA_DEF_DEF_  "GenSigSendOnInit" "Not Initialized";
BA_DEF_DEF_  "GenSigSendType" "NoSigSendType";
BA_DEF_DEF_  "GenMsgILSupport" "Yes";
BA_DEF_DEF_  "DiagRequest" "No";
BA_DEF_DEF_  "DiagResponse" "No";
BA_DEF_DEF_  "DiagState" "No";
BA_DEF_DEF_  "MessageSubnet" "Body";
BA_DEF_DEF_  "ECU_Id" 0;
BA_DEF_DEF_  "ILUsed" "Yes";
BA_DEF_DEF_  "SourceId" 0;
BA_DEF_DEF_  "NmAsrNode" "Yes";
BA_DEF_DEF_  "NmAsrNodeIdentifier" 0;
BA_DEF_DEF_  "NmAsrCanMsgReducedTime" 0;
BA_DEF_DEF_  "DBName" "SubCAN";
BA_DEF_DEF_  "NmType" "NmAsr";
BA_DEF_DEF_  "Baudrate" 500000;
BA_DEF_DEF_  "BusOffRecoveryTime" 160;
BA_DEF_DEF_  "Manufacturer" "GM";
BA_DEF_DEF_  "SamplePointMin" 81.25;
BA_DEF_DEF_  "SamplePointMax" 80;
BA_DEF_DEF_  "SyncJumpWidthMin" 4;
BA_DEF_DEF_  "SyncJumpWidthMax" 3;
BA_DEF_DEF_  "BusType" "CAN";
BA_DEF_DEF_  "NmAsrMessageCount" 16;
BA_DEF_DEF_  "NmAsrBaseAddress" 0;
BA_DEF_DEF_  "NmAsrTimeoutTime" 1500;
BA_DEF_DEF_  "NmAsrWaitBusSleepTime" 750;
BA_DEF_DEF_  "NmAsrRepeatMessageTime" 400;
BA_DEF_DEF_  "NmAsrCanMsgCycleTime" 1000;
BA_DEF_DEF_  "GenMsgCycleTime" 0;
BA_DEF_DEF_REL_ "GenSigTimeoutMsg" 0;
BA_DEF_DEF_REL_ "GenSigTimeoutTime" 0;
BA_DEF_DEF_ "NodeLayerModules" "";
BA_ "BusOffRecoveryTime" 200;
BA_ "NmAsrBaseAddress" 1312;
BA_ "NmAsrTimeoutTime" 1000;
BA_ "NmAsrWaitBusSleepTime" 5000;
BA_ "NmAsrCanMsgCycleTime" 200;
BA_ "DBName" "PB";
BA_ "SourceId" BU_ RRLCMA 1;
BA_ "ECU_Id" BU_ RRLCMA 1;
BA_ "NmAsrCanMsgReducedTime" BU_ RLLCMA 500;
BA_ "NmAsrNodeIdentifier" BU_ RLLCMA 1;
BA_ "MessageSubnet" BO_ 2161836032 1;
BA_ "GenMsgSendType" BO_ 459 0;
BA_ "GenMsgCycleTime" BO_ 459 20;
BA_ "MessageSubnet" BO_ 459 1;
BA_ "GenMsgSendType" BO_ 461 0;
BA_ "GenMsgCycleTime" BO_ 461 20;
BA_ "MessageSubnet" BO_ 461 1;
BA_ "GenMsgSendType" BO_ 480 0;
BA_ "GenMsgCycleTime" BO_ 480 20;
BA_ "MessageSubnet" BO_ 480 1;
BA_ "GenMsgSendType" BO_ 481 0;
BA_ "GenMsgCycleTime" BO_ 481 20;
BA_ "MessageSubnet" BO_ 481 1;
BA_ "GenMsgSendType" BO_ 485 0;
BA_ "GenMsgCycleTime" BO_ 485 20;
BA_ "MessageSubnet" BO_ 485 1;
BA_ "GenMsgSendType" BO_ 486 0;
BA_ "GenMsgCycleTime" BO_ 486 20;
BA_ "MessageSubnet" BO_ 486 1;
BA_ "GenMsgSendType" BO_ 489 0;
BA_ "GenMsgCycleTime" BO_ 489 20;
BA_ "MessageSubnet" BO_ 489 1;
BA_ "GenMsgSendType" BO_ 491 0;
BA_ "GenMsgCycleTime" BO_ 491 20;
BA_ "MessageSubnet" BO_ 491 1;
BA_ "GenMsgSendType" BO_ 494 0;
BA_ "GenMsgCycleTime" BO_ 494 20;
BA_ "MessageSubnet" BO_ 494 1;
BA_ "GenMsgSendType" BO_ 495 0;
BA_ "GenMsgCycleTime" BO_ 495 20;
BA_ "MessageSubnet" BO_ 495 1;
BA_ "GenMsgSendType" BO_ 498 0;
BA_ "GenMsgCycleTime" BO_ 498 20;
BA_ "MessageSubnet" BO_ 498 1;
BA_ "GenMsgSendType" BO_ 773 0;
BA_ "GenMsgCycleTime" BO_ 773 100;
BA_ "MessageSubnet" BO_ 773 1;
BA_ "GenMsgSendType" BO_ 774 0;
BA_ "GenMsgCycleTime" BO_ 774 100;
BA_ "MessageSubnet" BO_ 774 1;
BA_ "GenMsgSendType" BO_ 789 0;
BA_ "GenMsgCycleTime" BO_ 789 100;
BA_ "MessageSubnet" BO_ 789 1;
BA_ "GenMsgSendType" BO_ 790 0;
BA_ "GenMsgCycleTime" BO_ 790 100;
BA_ "MessageSubnet" BO_ 790 1;
BA_ "GenMsgSendType" BO_ 858 0;
BA_ "GenMsgCycleTime" BO_ 858 500;
BA_ "MessageSubnet" BO_ 858 1;
BA_ "GenMsgSendType" BO_ 1358 0;
BA_ "GenMsgCycleTime" BO_ 1358 200;
BA_ "MessageSubnet" BO_ 1358 1;
BA_ "GenMsgSendType" BO_ 1359 0;
BA_ "GenMsgCycleTime" BO_ 1359 200;
BA_ "MessageSubnet" BO_ 1359 1;
BA_ "GenMsgSendType" BO_ 1371 0;
BA_ "GenMsgCycleTime" BO_ 1371 200;
BA_ "MessageSubnet" BO_ 1371 1;
BA_ "GenMsgILSupport" BO_ 1870 0;
BA_ "DiagRequest" BO_ 1870 1;
BA_ "MessageSubnet" BO_ 1870 1;
BA_ "GenMsgILSupport" BO_ 1883 0;
BA_ "DiagRequest" BO_ 1883 1;
BA_ "MessageSubnet" BO_ 1883 1;
BA_ "GenMsgILSupport" BO_ 1998 0;
BA_ "DiagResponse" BO_ 1998 1;
BA_ "MessageSubnet" BO_ 1998 1;
BA_ "GenMsgILSupport" BO_ 2011 0;
BA_ "DiagResponse" BO_ 2011 1;
BA_ "MessageSubnet" BO_ 2011 1;
BA_ "DiagState" BO_ 2015 1;
BA_ "MessageSubnet" BO_ 2015 1;
BA_ "NodeLayerModules" BU_ GWM "CANoeILNLVector.dll,AsrNM33.dll";
BA_ "NodeLayerModules" BU_ RLLCMA "CANoeILNLVector.dll,AsrNM33.dll";
BA_ "NodeLayerModules" BU_ RRLCMA "CANoeILNLVector.dll,AsrNM33.dll";
BA_ "NodeLayerModules" BU_ Tester "CANoeILNLVector.dll,AsrNM33.dll";
BA_REL_ "GenSigTimeoutMsg" BU_SG_REL_ RRLCMA SG_ 459 LCU_RghtRrATL01Cmd 459;
BA_REL_ "GenSigTimeoutTime" BU_SG_REL_ RRLCMA SG_ 459 LCU_RghtRrATL01Cmd 500;
BA_REL_ "GenSigTimeoutMsg" BU_SG_REL_ RLLCMA SG_ 461 LCU_LftRrATL01Cmd 461;
BA_REL_ "GenSigTimeoutTime" BU_SG_REL_ RLLCMA SG_ 461 LCU_LftRrATL01Cmd 500;
BA_REL_ "GenSigTimeoutMsg" BU_SG_REL_ RRLCMA SG_ 480 LCU_RghtRrAPL01Cmd 480;
BA_REL_ "GenSigTimeoutTime" BU_SG_REL_ RRLCMA SG_ 480 LCU_RghtRrAPL01Cmd 500;
BA_REL_ "GenSigTimeoutMsg" BU_SG_REL_ RLLCMA SG_ 481 LCU_LftRrAPL01Cmd 481;
BA_REL_ "GenSigTimeoutTime" BU_SG_REL_ RLLCMA SG_ 481 LCU_LftRrAPL01Cmd 500;
BA_REL_ "GenSigTimeoutMsg" BU_SG_REL_ RRLCMA SG_ 485 LCU_RghtRrAPL09Cmd 485;
BA_REL_ "GenSigTimeoutTime" BU_SG_REL_ RRLCMA SG_ 485 LCU_RghtRrAPL09Cmd 500;
BA_REL_ "GenSigTimeoutMsg" BU_SG_REL_ RLLCMA SG_ 486 LCU_LftRrAPL09Cmd 486;
BA_REL_ "GenSigTimeoutTime" BU_SG_REL_ RLLCMA SG_ 486 LCU_LftRrAPL09Cmd 500;
BA_REL_ "GenSigTimeoutMsg" BU_SG_REL_ RRLCMA SG_ 489 LCU_LightShwSts 489;
BA_REL_ "GenSigTimeoutTime" BU_SG_REL_ RRLCMA SG_ 489 LCU_LightShwSts 500;
BA_REL_ "GenSigTimeoutMsg" BU_SG_REL_ RLLCMA SG_ 489 LCU_LightShwSts 489;
BA_REL_ "GenSigTimeoutTime" BU_SG_REL_ RLLCMA SG_ 489 LCU_LightShwSts 500;
BA_REL_ "GenSigTimeoutMsg" BU_SG_REL_ RLLCMA SG_ 491 LCU_LftRrAPL17Cmd 491;
BA_REL_ "GenSigTimeoutTime" BU_SG_REL_ RLLCMA SG_ 491 LCU_LftRrAPL17Cmd 500;
BA_REL_ "GenSigTimeoutMsg" BU_SG_REL_ RRLCMA SG_ 494 LCU_RghtRrAPL17Cmd 494;
BA_REL_ "GenSigTimeoutTime" BU_SG_REL_ RRLCMA SG_ 494 LCU_RghtRrAPL17Cmd 500;
BA_REL_ "GenSigTimeoutMsg" BU_SG_REL_ RLLCMA SG_ 495 LCU_LftRrAPL25Cmd 495;
BA_REL_ "GenSigTimeoutTime" BU_SG_REL_ RLLCMA SG_ 495 LCU_LftRrAPL25Cmd 500;
BA_REL_ "GenSigTimeoutMsg" BU_SG_REL_ RRLCMA SG_ 498 LCU_RghtRrAPL25Cmd 498;
BA_REL_ "GenSigTimeoutTime" BU_SG_REL_ RRLCMA SG_ 498 LCU_RghtRrAPL25Cmd 500;
BA_REL_ "GenSigTimeoutMsg" BU_SG_REL_ RRLCMA SG_ 858 ACU_Time_Year 858;
BA_REL_ "GenSigTimeoutTime" BU_SG_REL_ RRLCMA SG_ 858 ACU_Time_Year 3000;
BA_REL_ "GenSigTimeoutMsg" BU_SG_REL_ RLLCMA SG_ 858 ACU_Time_Year 858;
BA_REL_ "GenSigTimeoutTime" BU_SG_REL_ RLLCMA SG_ 858 ACU_Time_Year 3000;
BA_REL_ "GenSigTimeoutMsg" BU_SG_REL_ RRLCMA SG_ 1359 GWM_NodeAddress 1359;
BA_REL_ "GenSigTimeoutTime" BU_SG_REL_ RRLCMA SG_ 1359 GWM_NodeAddress 1000;
BA_REL_ "GenSigTimeoutMsg" BU_SG_REL_ RLLCMA SG_ 1359 GWM_NodeAddress 1359;
BA_REL_ "GenSigTimeoutTime" BU_SG_REL_ RLLCMA SG_ 1359 GWM_NodeAddress 1000;
VAL_ 489 EMS_BatteryReadySt 0 "Not on crank" 1 "On crank" ;
VAL_ 489 LCU_WelShwSts 0 "no show" 1 "welcome mode 1" 2 "welcome mode 2" 3 "welcome mode 3" 4 "welcome mode 4" 5 "welcome mode 5" 6 "welcome mode 6" 7 "reserved" 8 "reserved" 9 "reserved" 10 "reserved" 11 "reserved" 12 "reserved" 13 "reserved" 14 "reserved" 15 "reserved" ;
VAL_ 489 LCU_LightShwSts 0 "no show" 1 "light show mode 1" 2 "light show mode 2" 3 "light show mode 3" 4 "light show mode 4" 5 "light show mode 5" 6 "light show mode 6" 7 "reserved" 8 "reserved" 9 "reserved" 10 "reserved" 11 "reserved" 12 "reserved" 13 "reserved" 14 "reserved" 15 "reserved" ;
VAL_ 489 LCU_LftFrntPlSts 0 "off" 1 "PL mode on" 2 "special mode on" ;
VAL_ 489 LCU_RghtDrlSts 0 "off" 1 "on" ;
VAL_ 489 LCU_LftDrlSts 0 "off" 1 "on" ;
VAL_ 489 LCU_RghtTrnSts 0 "off" 1 "on" ;
VAL_ 489 LCU_LftTrnSts 0 "off" 1 "on" ;
VAL_ 489 LCU_FrntFogSts 0 "off" 1 "on" ;
VAL_ 489 LCU_HbSts 0 "off" 1 "normal on" 2 "ADB mode" ;
VAL_ 489 LCU_LbSts 0 "off" 1 "on" ;
VAL_ 489 LCU_RghtRrPlSts 0 "off" 1 "on" ;
VAL_ 489 LCU_LftRrPlSts 0 "off" 1 "on" ;
VAL_ 489 LCU_RghtFrntPlSts 0 "off" 1 "PL mode on" 2 "special mode on" ;
VAL_ 489 LCU_Fan2Cmd 0 "off" 1 "on" ;
VAL_ 489 LCU_Fan1Cmd 0 "off" 1 "on" ;
VAL_ 489 LCU_RrFogSts 0 "off" 1 "on" ;
VAL_ 489 LCU_StopSts 0 "off" 1 "on" ;
VAL_ 489 BCS_VehSpdVD 0 "Not Valid" 1 "Valid" ;
VAL_ 489 EMS_EngCrankSt 0 "Not on crank" 1 "On crank" ;
VAL_ 489 EMS_EngSt 0 "Not run" 1 "Run" ;
VAL_ 773 RLLCMAErrSts 0 "normal" 1 "fail" ;
VAL_ 773 RLLCMA_LftExtRLamp3Sts 0 "off" 1 "on" 2 "fail" ;
VAL_ 773 RLLCMA_LftExtRLamp2Sts 0 "off" 1 "on" 2 "fail" ;
VAL_ 773 RLLCMA_LftExtRLamp1Sts 0 "off" 1 "on" 2 "fail" ;
VAL_ 773 RLLCMA_LftRPLSts 0 "off" 1 "on" 2 "fail" ;
VAL_ 773 RLLCMA_LftRTLSts 0 "off" 1 "on" 2 "fail" ;
VAL_ 773 RLLCMA_LftFltIn2Sts 0 "low level" 1 "high level" ;
VAL_ 773 RLLCMA_LftFltIn1Sts 0 "low level" 1 "high level" ;
VAL_ 773 RLLCMA_LftRStpLgcSts 0 "low level" 1 "high level" ;
VAL_ 773 RLLCMA_LftRKL15Sts 0 "low level" 1 "high level" ;
VAL_ 774 RRLCMAErrSts 0 "normal" 1 "fail" ;
VAL_ 774 RRLCMA_RghtExtRLamp3Sts 0 "off" 1 "on" 2 "fail" ;
VAL_ 774 RRLCMA_RghtExtRLamp2Sts 0 "off" 1 "on" 2 "fail" ;
VAL_ 774 RRLCMA_RghtExtRLamp1Sts 0 "off" 1 "on" 2 "fail" ;
VAL_ 774 RRLCMA_RghtRPLSts 0 "off" 1 "on" 2 "fail" ;
VAL_ 774 RRLCMA_RghtRTLSts 0 "off" 1 "on" 2 "fail" ;
VAL_ 774 RRLCMA_RghtFltIn2Sts 0 "low level" 1 "high level" ;
VAL_ 774 RRLCMA_RghtFltIn1Sts 0 "low level" 1 "high level" ;
VAL_ 774 RRLCMA_RghtRStpLgcSts 0 "low level" 1 "high level" ;
VAL_ 774 RRLCMA_RghtRKL15Sts 0 "low level" 1 "high level" ;
VAL_ 789 RLLCMA_Bin2Err 0 "normal" 1 "fail" ;
VAL_ 789 RLLCMA_Bin1Err 0 "normal" 1 "fail" ;
VAL_ 789 RLLCMA_HsssErr 0 "normal" 1 "fail" ;
VAL_ 789 RLLCMA_Cv2Err 0 "normal" 1 "fail" ;
VAL_ 789 RLLCMA_Cv1Err 0 "normal" 1 "fail" ;
VAL_ 789 RLLCMA_LdoErr 0 "normal" 1 "fail" ;
VAL_ 789 RLLCMA_LostLCU 0 "normal" 1 "fail" ;
VAL_ 789 RLLCMA_BusOff 0 "normal" 1 "fail" ;
VAL_ 789 RLLCMA_Uv 0 "normal" 1 "fail" ;
VAL_ 789 RLLCMA_Ov 0 "normal" 1 "fail" ;
VAL_ 789 RLLCMA_Mtrx7Lst 0 "normal" 1 "fail" ;
VAL_ 789 RLLCMA_Mtrx6Lst 0 "normal" 1 "fail" ;
VAL_ 789 RLLCMA_Mtrx5Lst 0 "normal" 1 "fail" ;
VAL_ 789 RLLCMA_Mtrx4Lst 0 "normal" 1 "fail" ;
VAL_ 789 RLLCMA_Mtrx3Lst 0 "normal" 1 "fail" ;
VAL_ 789 RLLCMA_Mtrx2Lst 0 "normal" 1 "fail" ;
VAL_ 789 RLLCMA_Mtrx1Lst 0 "normal" 1 "fail" ;
VAL_ 789 RLLCMA_Mtrx0Lst 0 "normal" 1 "fail" ;
VAL_ 789 RLLCMA_Mtrx7LedErr 0 "normal" 1 "fail" ;
VAL_ 789 RLLCMA_Mtrx6LedErr 0 "normal" 1 "fail" ;
VAL_ 789 RLLCMA_Mtrx5LedErr 0 "normal" 1 "fail" ;
VAL_ 789 RLLCMA_Mtrx4LedErr 0 "normal" 1 "fail" ;
VAL_ 789 RLLCMA_Mtrx3LedErr 0 "normal" 1 "fail" ;
VAL_ 789 RLLCMA_Mtrx2LedErr 0 "normal" 1 "fail" ;
VAL_ 789 RLLCMA_Mtrx1LedErr 0 "normal" 1 "fail" ;
VAL_ 789 RLLCMA_Mtrx0LedErr 0 "normal" 1 "fail" ;
VAL_ 789 RLLCMA_FltIn2Warning 0 "normal" 1 "fail" ;
VAL_ 789 RLLCMA_FltIn1Warning 0 "normal" 1 "fail" ;
VAL_ 790 RRLCMA_Bin2Err 0 "normal" 1 "fail" ;
VAL_ 790 RRLCMA_Bin1Err 0 "normal" 1 "fail" ;
VAL_ 790 RRLCMA_HsssErr 0 "normal" 1 "fail" ;
VAL_ 790 RRLCMA_Cv2Err 0 "normal" 1 "fail" ;
VAL_ 790 RRLCMA_Cv1Err 0 "normal" 1 "fail" ;
VAL_ 790 RRLCMA_LdoErr 0 "normal" 1 "fail" ;
VAL_ 790 RRLCMA_LostLCU 0 "normal" 1 "fail" ;
VAL_ 790 RRLCMA_BusOff 0 "normal" 1 "fail" ;
VAL_ 790 RRLCMA_Uv 0 "normal" 1 "fail" ;
VAL_ 790 RRLCMA_Ov 0 "normal" 1 "fail" ;
VAL_ 790 RRLCMA_Mtrx7Lst 0 "normal" 1 "fail" ;
VAL_ 790 RRLCMA_Mtrx6Lst 0 "normal" 1 "fail" ;
VAL_ 790 RRLCMA_Mtrx5Lst 0 "normal" 1 "fail" ;
VAL_ 790 RRLCMA_Mtrx4Lst 0 "normal" 1 "fail" ;
VAL_ 790 RRLCMA_Mtrx3Lst 0 "normal" 1 "fail" ;
VAL_ 790 RRLCMA_Mtrx2Lst 0 "normal" 1 "fail" ;
VAL_ 790 RRLCMA_Mtrx1Lst 0 "normal" 1 "fail" ;
VAL_ 790 RRLCMA_Mtrx0Lst 0 "normal" 1 "fail" ;
VAL_ 790 RRLCMA_Mtrx7LedErr 0 "normal" 1 "fail" ;
VAL_ 790 RRLCMA_Mtrx6LedErr 0 "normal" 1 "fail" ;
VAL_ 790 RRLCMA_Mtrx5LedErr 0 "normal" 1 "fail" ;
VAL_ 790 RRLCMA_Mtrx4LedErr 0 "normal" 1 "fail" ;
VAL_ 790 RRLCMA_Mtrx3LedErr 0 "normal" 1 "fail" ;
VAL_ 790 RRLCMA_Mtrx2LedErr 0 "normal" 1 "fail" ;
VAL_ 790 RRLCMA_Mtrx1LedErr 0 "normal" 1 "fail" ;
VAL_ 790 RRLCMA_Mtrx0LedErr 0 "normal" 1 "fail" ;
VAL_ 790 RRLCMA_FltIn2Warning 0 "normal" 1 "fail" ;
VAL_ 790 RRLCMA_FltIn1Warning 0 "normal" 1 "fail" ;
